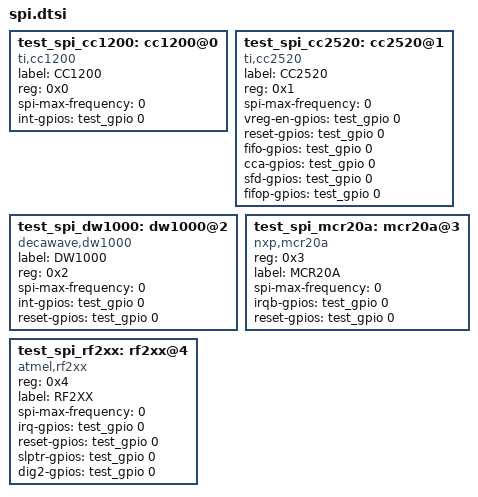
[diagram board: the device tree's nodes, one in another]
/*
 * Copyright (c) 2021, Commonwealth Scientific and Industrial Research
 * Organisation (CSIRO) ABN 41 687 119 230.
 *
 * SPDX-License-Identifier: Apache-2.0
 *
 * Application overlay for spi devices
 */

test_spi_cc1200: cc1200@0 {
	compatible = "ti,cc1200";
	label = "CC1200";
	reg = <0x0>;
	spi-max-frequency = <0>;
	int-gpios = <&test_gpio 0 0>;
	status= "okay";
};

test_spi_cc2520: cc2520@1 {
	compatible = "ti,cc2520";
	label = "CC2520";
	reg = <0x1>;
	spi-max-frequency = <0>;
	vreg-en-gpios = <&test_gpio 0 0>;
	reset-gpios = <&test_gpio 0 0>;
	fifo-gpios = <&test_gpio 0 0>;
	cca-gpios = <&test_gpio 0 0>;
	sfd-gpios = <&test_gpio 0 0>;
	fifop-gpios = <&test_gpio 0 0>;
	status= "okay";
};

test_spi_dw1000: dw1000@2 {
	compatible = "decawave,dw1000";
	label = "DW1000";
	reg = <0x2>;
	spi-max-frequency = <0>;
	int-gpios = <&test_gpio 0 0>;
	reset-gpios =<&test_gpio 0 0>;
	status= "okay";
};

test_spi_mcr20a: mcr20a@3 {
	compatible = "nxp,mcr20a";
	reg = <0x3>;
	label = "MCR20A";
	spi-max-frequency = <0>;
	irqb-gpios = <&test_gpio 0 0>;
	reset-gpios = <&test_gpio 0 0>;
	status = "okay";
};

test_spi_rf2xx: rf2xx@4 {
	compatible = "atmel,rf2xx";
	reg = <0x4>;
	label = "RF2XX";
	spi-max-frequency = <0>;
	irq-gpios = <&test_gpio 0 0>;
	reset-gpios = <&test_gpio 0 0>;
	slptr-gpios = <&test_gpio 0 0>;
	dig2-gpios = <&test_gpio 0 0>;
	status = "okay";
};
